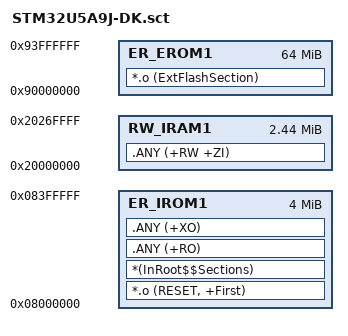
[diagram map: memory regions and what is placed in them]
; *************************************************************
; *** Scatter-Loading Description File generated by uVision ***
; *************************************************************

LR_IROM1 0x08000000 0x00400000  {    ; load region size_region
  ER_IROM1 0x08000000 0x00400000  {  ; load address = execution address
   *.o (RESET, +First)
   *(InRoot$$Sections)
   .ANY (+RO)
   .ANY (+XO)
  }
  
  RW_IRAM1 0x20000000 0x00270000  {  ; RW data
   .ANY (+RW +ZI)
  }
}

LR_EROM1 0x90000000 0x04000000  {    ; load region size_region
  ER_EROM1 0x90000000 0x04000000  {  ; load address = execution address
   *.o (ExtFlashSection)
  }
}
